[part 1 of 2: package /EcuExtract]
AUTOSAR XML (schema 4-2-1)
package /EcuExtract
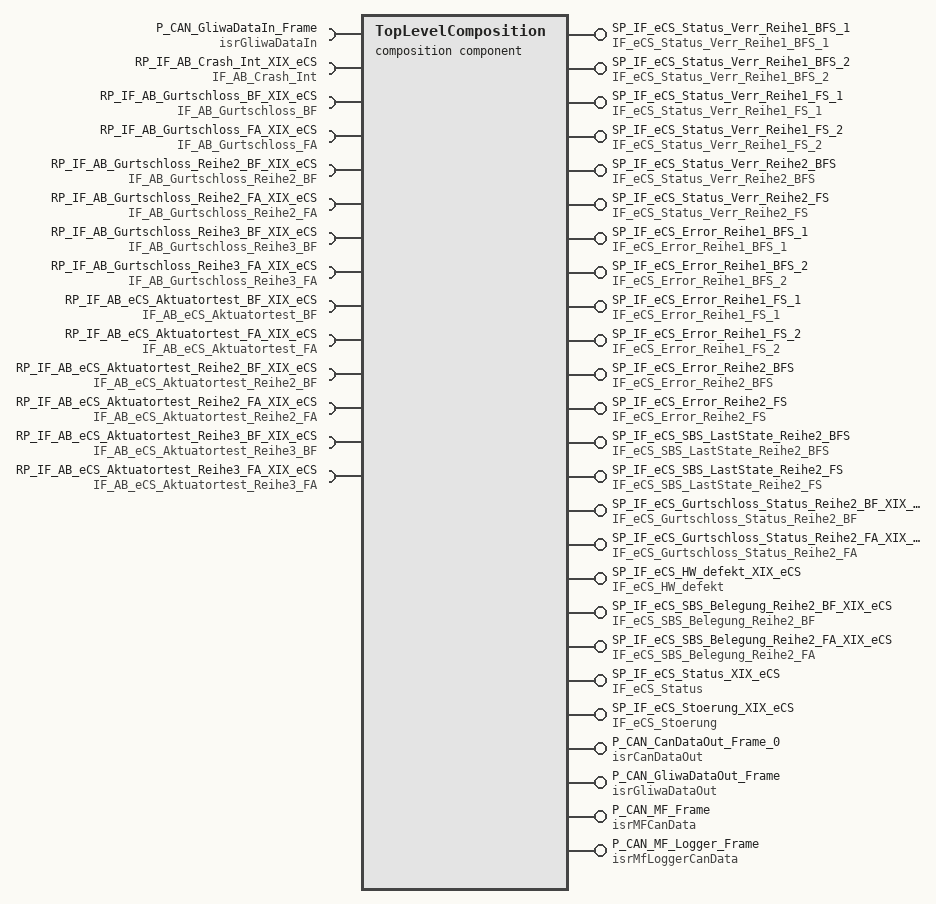
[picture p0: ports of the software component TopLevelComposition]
  composition sw component type TopLevelComposition
    require port P_CAN_GliwaDataIn_Frame: required-interface=isrGliwaDataIn
    14 x provide port:
      SP_IF_eCS_Status_Verr_Reihe1_BFS_1: provided-interface=IF_eCS_Status_Verr_Reihe1_BFS_1
      SP_IF_eCS_Status_Verr_Reihe1_BFS_2: provided-interface=IF_eCS_Status_Verr_Reihe1_BFS_2
      SP_IF_eCS_Status_Verr_Reihe1_FS_1: provided-interface=IF_eCS_Status_Verr_Reihe1_FS_1
      SP_IF_eCS_Status_Verr_Reihe1_FS_2: provided-interface=IF_eCS_Status_Verr_Reihe1_FS_2
      SP_IF_eCS_Status_Verr_Reihe2_BFS: provided-interface=IF_eCS_Status_Verr_Reihe2_BFS
      SP_IF_eCS_Status_Verr_Reihe2_FS: provided-interface=IF_eCS_Status_Verr_Reihe2_FS
      SP_IF_eCS_Error_Reihe1_BFS_1: provided-interface=IF_eCS_Error_Reihe1_BFS_1
      SP_IF_eCS_Error_Reihe1_BFS_2: provided-interface=IF_eCS_Error_Reihe1_BFS_2
      SP_IF_eCS_Error_Reihe1_FS_1: provided-interface=IF_eCS_Error_Reihe1_FS_1
      SP_IF_eCS_Error_Reihe1_FS_2: provided-interface=IF_eCS_Error_Reihe1_FS_2
      SP_IF_eCS_Error_Reihe2_BFS: provided-interface=IF_eCS_Error_Reihe2_BFS
      SP_IF_eCS_Error_Reihe2_FS: provided-interface=IF_eCS_Error_Reihe2_FS
      SP_IF_eCS_SBS_LastState_Reihe2_BFS: provided-interface=IF_eCS_SBS_LastState_Reihe2_BFS
      SP_IF_eCS_SBS_LastState_Reihe2_FS: provided-interface=IF_eCS_SBS_LastState_Reihe2_FS
    13 x require port:
      RP_IF_AB_Crash_Int_XIX_eCS: required-interface=IF_AB_Crash_Int
      RP_IF_AB_Gurtschloss_BF_XIX_eCS: required-interface=IF_AB_Gurtschloss_BF
      RP_IF_AB_Gurtschloss_FA_XIX_eCS: required-interface=IF_AB_Gurtschloss_FA
      RP_IF_AB_Gurtschloss_Reihe2_BF_XIX_eCS: required-interface=IF_AB_Gurtschloss_Reihe2_BF
      RP_IF_AB_Gurtschloss_Reihe2_FA_XIX_eCS: required-interface=IF_AB_Gurtschloss_Reihe2_FA
      RP_IF_AB_Gurtschloss_Reihe3_BF_XIX_eCS: required-interface=IF_AB_Gurtschloss_Reihe3_BF
      RP_IF_AB_Gurtschloss_Reihe3_FA_XIX_eCS: required-interface=IF_AB_Gurtschloss_Reihe3_FA
      RP_IF_AB_eCS_Aktuatortest_BF_XIX_eCS: required-interface=IF_AB_eCS_Aktuatortest_BF
      RP_IF_AB_eCS_Aktuatortest_FA_XIX_eCS: required-interface=IF_AB_eCS_Aktuatortest_FA
      RP_IF_AB_eCS_Aktuatortest_Reihe2_BF_XIX_eCS: required-interface=IF_AB_eCS_Aktuatortest_Reihe2_BF
      RP_IF_AB_eCS_Aktuatortest_Reihe2_FA_XIX_eCS: required-interface=IF_AB_eCS_Aktuatortest_Reihe2_FA
      RP_IF_AB_eCS_Aktuatortest_Reihe3_BF_XIX_eCS: required-interface=IF_AB_eCS_Aktuatortest_Reihe3_BF
      RP_IF_AB_eCS_Aktuatortest_Reihe3_FA_XIX_eCS: required-interface=IF_AB_eCS_Aktuatortest_Reihe3_FA
    11 x provide port:
      SP_IF_eCS_Gurtschloss_Status_Reihe2_BF_XIX_eCS: provided-interface=IF_eCS_Gurtschloss_Status_Reihe2_BF
      SP_IF_eCS_Gurtschloss_Status_Reihe2_FA_XIX_eCS: provided-interface=IF_eCS_Gurtschloss_Status_Reihe2_FA
      SP_IF_eCS_HW_defekt_XIX_eCS: provided-interface=IF_eCS_HW_defekt
      SP_IF_eCS_SBS_Belegung_Reihe2_BF_XIX_eCS: provided-interface=IF_eCS_SBS_Belegung_Reihe2_BF
      SP_IF_eCS_SBS_Belegung_Reihe2_FA_XIX_eCS: provided-interface=IF_eCS_SBS_Belegung_Reihe2_FA
      SP_IF_eCS_Status_XIX_eCS: provided-interface=IF_eCS_Status
      SP_IF_eCS_Stoerung_XIX_eCS: provided-interface=IF_eCS_Stoerung
      P_CAN_CanDataOut_Frame_0: provided-interface=isrCanDataOut
      P_CAN_GliwaDataOut_Frame: provided-interface=isrGliwaDataOut
      P_CAN_MF_Frame: provided-interface=isrMFCanData
      P_CAN_MF_Logger_Frame: provided-interface=isrMfLoggerCanData
    32 x component:
      ACC: type=ACC
      ATM: type=ATM
      AdcIf: type=AdcIf
      BswMIf: type=BswMIf
      CIL: type=CIL
      DIA: type=DIA
      DcmIf: type=DcmIf
      DemIf: type=DemIf
      DioIf: type=DioIf
      EFX: type=EFX
      EIM: type=EIM
      EcuMIf: type=EcuMIf
      FSM: type=FSM
      IoHwAb: type=IoHwAb
      LPM: type=LPM
      MIC: type=MIC
      McuIf: type=McuIf
      NVP: type=NVP
      NmIf: type=NmIf
      NvmIf: type=NvmIf
      OsIf: type=OsIf
      PwmIf: type=PwmIf
      RCM: type=RCM
      SAD: type=SAD
      SBC: type=SBC
      STM: type=STM
      SpiIf: type=SpiIf
      T1: type=T1
      eCS: type=eCS
      Dcm: type=Dcm
      Dem: type=Dem
      NvM: type=NvM
    connect ACC.pseAccRestartInit -> LPM.pclAccRestartInit
    connect ACC.pseCheckAccAlarmbPin -> ATM.pclCheckAccAlarmbPin
    connect ACC.psr3DAcceleration -> CIL.prr3DAcceleration
    connect ACC.psr3DAcceleration -> DIA.prr3DAcceleration
    connect ACC.psrACCServices -> FSM.prrACCServices
    connect ACC.psrAccStatusFailiureSource -> CIL.prrAccStatusFailiureSource
    connect ACC.psrAccelMtrPerSecSqd -> CIL.prrAccelMtrPerSecSqd
    connect ACC.psrAccelMtrPerSecSqd -> eCS.prrAccelMtrPerSecSqd
    connect ACC.pseAccTemperatureSpiData -> IoHwAb.pclAccSpiData
    connect DioIf.psrDioIfServices -> ACC.pclDioIfServices
    connect FSM.psrSolenoidProfile -> ACC.prrSolenoidProfile
    connect SpiIf.ptrpSpiIfServicesACC -> ACC.ptrrSpiIfServices
    connect ATM.pseAutotestServices -> FSM.pclAutotestServices
    connect ATM.pseAutotestServices -> IoHwAb.pclAutotestServices
    connect ATM.pseAutotestServices -> SAD.pclAutotestServices
    connect ATM.ptrpAtmServicesBswMIf -> BswMIf.ptrrAtmServicesBswMIf
    connect AdcIf.pseCheckAdcCalib -> ATM.pclCheckAdcCalib
    connect AdcIf.pseCheckAdc -> ATM.pclCheckAdc
    connect MIC.pseRunEepromMemoryCorruption -> ATM.pclRunEepromMemoryCorruption
    connect NvmIf.pseRunEepromMemoryNotProgrammed -> ATM.pclRunEepromMemoryNotProgrammed
    connect MIC.pseRunPFlashMemoryCorruption -> ATM.pclRunPFlashMemoryCorruption
    connect MIC.pseRunRamMemoryCorruption -> ATM.pclRunRamMemoryCorruption
    connect RCM.pseRunResetCause -> ATM.pclRunResetCause
    connect EIM.pseInjectError -> ATM.pclInjectError
    connect FSM.pseModeManagement -> ATM.pclModeManagement
    connect IoHwAb.pseCheckPowerSupplyOV -> ATM.pclCheckPowerSupplyOV
    connect IoHwAb.pseCheckPowerSupplyUV -> ATM.pclCheckPowerSupplyUV
    connect IoHwAb.pseEcuOverTemperature -> ATM.pclEcuOverTemperature
    connect McuIf.pseCheckCrcOnMcuRegisters -> ATM.pclCheckCrcOnMcuRegisters
    connect McuIf.pseCheckMcuSelfTest -> ATM.pclCheckMcuSelfTest
    connect SAD.pseCheckActuatorState -> ATM.pclCheckActuatorState
    connect SAD.pseCheckPowerStage -> ATM.pclCheckPowerStage
    connect SAD.pseCheckSolenoidOpenCircuit -> ATM.pclCheckOpenCircuit
    connect SAD.pseCheckSolenoidOvervoltage -> ATM.pclCheckSolenoidOvervoltage
    connect SAD.pseCheckSolenoidShortToGND -> ATM.pclCheckShortToGND
    connect SAD.pseCheckSolenoidShortToVBAT -> ATM.pclCheckShortToVBAT
    connect SBC.pseCheckSbcStatusInfo -> ATM.pclCheckSbcStatusInfo
    connect SBC.pseSbcWdgAutotest -> ATM.pclRunExtWDTest
    connect Dem.ASR42_Event_EVENT_ACC_STATUS_FAILURE -> ATM.pclEvtAccStatusFailure
    connect Dem.ASR42_Event_EVENT_ACTUATOR_OPEN_CIRCUIT -> ATM.pclEvtActuatorOpenCircuit
    connect Dem.ASR42_Event_EVENT_ACTUATOR_SHORT_TO_GND -> ATM.pclEvtActuatorShortToGND
    connect Dem.ASR42_Event_EVENT_ACTUATOR_SHORT_TO_VBAT -> ATM.pclEvtActuatorShortToVBAT
    connect Dem.ASR42_Event_EVENT_ACTUATOR_STATUS -> ATM.pclEvtActuatorState
    connect Dem.ASR42_Event_EVENT_ADC_CALIB -> ATM.pclEvtAdcCalibration
    connect Dem.ASR42_Event_EVENT_ADC_OUT_OF_ORDER -> ATM.pclEvtAdcOutOfOrder
    connect Dem.ASR42_Event_EVENT_DFLASH_MEM_CORRUPT -> ATM.pclEvtNvmEcc
    connect Dem.ASR42_Event_EVENT_ECU_OVER_TEMPERATURE -> ATM.pclEvtEcuoverTemperature
    connect Dem.ASR42_Event_EVENT_EXT_WDG_OUT_OF_ORDER -> ATM.pclEvtExtWdgOutOfOrder
    connect Dem.ASR42_Event_EVENT_MCU_CRC_REGISTERS -> ATM.pclEvtMcuCrcRegisters
    connect Dem.ASR42_Event_EVENT_MCU_SELFTEST -> ATM.pclEvtMcuSelftest
    connect Dem.ASR42_Event_EVENT_NVM_NOT_PRG -> ATM.pclEvtNvmNotPrg
    connect Dem.ASR42_Event_EVENT_PFLASH_MEM_CORRUPT -> ATM.pclEvtFlsEcc
    connect Dem.ASR42_Event_EVENT_POWER_STAGE_FAILIURE -> ATM.pclEvtPowerStageFailiure
    connect Dem.ASR42_Event_EVENT_POWER_SUPPLY_OV -> ATM.pclEvtPowerSupllyOV
    connect Dem.ASR42_Event_EVENT_POWER_SUPPLY_UV -> ATM.pclEvtPowerSupllyUV
    connect Dem.ASR42_Event_EVENT_RAM_MEM_CORRUPT -> ATM.pclEvtRamEcc
    connect Dem.ASR42_Event_EVENT_SBC_STATUS_FAILURE -> ATM.pclEvtSbcStatusFailiure
    connect Dem.ASR42_Event_EVENT_SOLENOID_OVERVOLTAGE -> ATM.pclEvtSolenoidOvervoltage
    connect Dem.ASR42_Event_EVENT_WARM_RESET -> ATM.pclEvtWarmReset
    connect AdcIf.prrAdcBufferServices -> IoHwAb.prrAdcBufferServices
    connect AdcIf.pseAdcIfServices -> LPM.pclAdcIfServices
    connect AdcIf.ptrpAdcIfServicesBswMIf -> BswMIf.ptrrAdcIfServicesBswMIf
    connect AdcIf.ptrpEcuMIfServicesAdcIf -> EcuMIf.ptrrEcuMIfServicesAdcIf
    connect AdcIf.pseRawAdcService -> IoHwAb.pclRawAdcService
    connect BswMIf.pseEcuStateTransitions -> NmIf.pclEcuStateTransitionBswMIf
    connect BswMIf.psePassengerOccupancyState -> IoHwAb.pclPassengerOccupancyState
    connect BswMIf.psrBswMIfServices -> FSM.prrBswMIfServices
    connect BswMIf.psrFsmSolenoidReqBswMIf -> FSM.prrEcsDiagRequest
    connect BswMIf.ptrpNmIfServicesBswMIf -> NmIf.ptrrNmIfServicesBswMIf
    connect CIL.pseSetEcuStateSignal -> BswMIf.pclCILGetEcuState
    connect CIL.ptrpCilServicesBswMIf -> BswMIf.ptrrCilServicesBswMIf
    connect DIA.ptrpDiaServicesBswMIf -> BswMIf.ptrrDiaServicesBswMIf
    connect FSM.ptrpFsmServicesBswMIf -> BswMIf.ptrrFsmServicesBswMIf
    connect LPM.ptrpLpmServicesBswMIf -> BswMIf.ptrrLpmServicesBswMIf
    connect MIC.p_ptrrMicServicesBswMIf -> BswMIf.ptrrMicServices
    connect McuIf.ptrpMcuIfServicesBswmIf -> BswMIf.ptrrMcuIfServicesBswMIf
    connect NvmIf.pseNvmIfServices -> BswMIf.pclNvmIfServices
    connect RCM.pseResetCauseNotification -> BswMIf.pclNotifyResetCause
    connect RCM.ptrpRcmServicesBswMIf -> BswMIf.ptrrRcmServicesBswMIf
    connect SAD.ptrpSadServicesBswMIf -> BswMIf.ptrrSadServicesBswMIf
    connect Dem.ASR42_OpCycle_DEM_OPCYC_POWER -> BswMIf.pclDemSetOpCycle
    delegate CIL.P_CAN_GliwaDataIn_Frame <-> outer port P_CAN_GliwaDataIn_Frame
    delegate CIL.SP_IF_eCS_Status_Verr_Reihe1_BFS_1 <-> outer port SP_IF_eCS_Status_Verr_Reihe1_BFS_1
    delegate CIL.SP_IF_eCS_Status_Verr_Reihe1_BFS_2 <-> outer port SP_IF_eCS_Status_Verr_Reihe1_BFS_2
    delegate CIL.SP_IF_eCS_Status_Verr_Reihe1_FS_1 <-> outer port SP_IF_eCS_Status_Verr_Reihe1_FS_1
    delegate CIL.SP_IF_eCS_Status_Verr_Reihe1_FS_2 <-> outer port SP_IF_eCS_Status_Verr_Reihe1_FS_2
    delegate CIL.SP_IF_eCS_Status_Verr_Reihe2_BFS <-> outer port SP_IF_eCS_Status_Verr_Reihe2_BFS
    delegate CIL.SP_IF_eCS_Status_Verr_Reihe2_FS <-> outer port SP_IF_eCS_Status_Verr_Reihe2_FS
    delegate CIL.SP_IF_eCS_Error_Reihe1_BFS_1 <-> outer port SP_IF_eCS_Error_Reihe1_BFS_1
    delegate CIL.SP_IF_eCS_Error_Reihe1_BFS_2 <-> outer port SP_IF_eCS_Error_Reihe1_BFS_2
    delegate CIL.SP_IF_eCS_Error_Reihe1_FS_1 <-> outer port SP_IF_eCS_Error_Reihe1_FS_1
    delegate CIL.SP_IF_eCS_Error_Reihe1_FS_2 <-> outer port SP_IF_eCS_Error_Reihe1_FS_2
    delegate CIL.SP_IF_eCS_Error_Reihe2_BFS <-> outer port SP_IF_eCS_Error_Reihe2_BFS
    delegate CIL.SP_IF_eCS_Error_Reihe2_FS <-> outer port SP_IF_eCS_Error_Reihe2_FS
    delegate CIL.SP_IF_eCS_SBS_LastState_Reihe2_BFS <-> outer port SP_IF_eCS_SBS_LastState_Reihe2_BFS
    delegate CIL.SP_IF_eCS_SBS_LastState_Reihe2_FS <-> outer port SP_IF_eCS_SBS_LastState_Reihe2_FS
    delegate CIL.RP_IF_AB_Crash_Int_XIX_Grundumfang_XIX_eCS <-> outer port RP_IF_AB_Crash_Int_XIX_eCS
    delegate CIL.RP_IF_AB_Gurtschloss_BF_XIX_Grundumfang_XIX_eCS <-> outer port RP_IF_AB_Gurtschloss_BF_XIX_eCS
    delegate CIL.RP_IF_AB_Gurtschloss_FA_XIX_Grundumfang_XIX_eCS <-> outer port RP_IF_AB_Gurtschloss_FA_XIX_eCS
    delegate CIL.RP_IF_AB_Gurtschloss_Reihe2_BF_XIX_Grundumfang_XIX_eCS <-> outer port RP_IF_AB_Gurtschloss_Reihe2_BF_XIX_eCS
    delegate CIL.RP_IF_AB_Gurtschloss_Reihe2_FA_XIX_Grundumfang_XIX_eCS <-> outer port RP_IF_AB_Gurtschloss_Reihe2_FA_XIX_eCS
    delegate CIL.RP_IF_AB_Gurtschloss_Reihe3_BF_XIX_Grundumfang_XIX_eCS <-> outer port RP_IF_AB_Gurtschloss_Reihe3_BF_XIX_eCS
    delegate CIL.RP_IF_AB_Gurtschloss_Reihe3_FA_XIX_Grundumfang_XIX_eCS <-> outer port RP_IF_AB_Gurtschloss_Reihe3_FA_XIX_eCS
    delegate CIL.RP_IF_AB_eCS_Aktuatortest_BF_XIX_Grundumfang_XIX_eCS <-> outer port RP_IF_AB_eCS_Aktuatortest_BF_XIX_eCS
    delegate CIL.RP_IF_AB_eCS_Aktuatortest_FA_XIX_Grundumfang_XIX_eCS <-> outer port RP_IF_AB_eCS_Aktuatortest_FA_XIX_eCS
    delegate CIL.RP_IF_AB_eCS_Aktuatortest_Reihe2_BF_XIX_Grundumfang_XIX_eCS <-> outer port RP_IF_AB_eCS_Aktuatortest_Reihe2_BF_XIX_eCS
    delegate CIL.RP_IF_AB_eCS_Aktuatortest_Reihe2_FA_XIX_Grundumfang_XIX_eCS <-> outer port RP_IF_AB_eCS_Aktuatortest_Reihe2_FA_XIX_eCS
    delegate CIL.RP_IF_AB_eCS_Aktuatortest_Reihe3_BF_XIX_Grundumfang_XIX_eCS <-> outer port RP_IF_AB_eCS_Aktuatortest_Reihe3_BF_XIX_eCS
    delegate CIL.RP_IF_AB_eCS_Aktuatortest_Reihe3_FA_XIX_Grundumfang_XIX_eCS <-> outer port RP_IF_AB_eCS_Aktuatortest_Reihe3_FA_XIX_eCS
    delegate CIL.SP_IF_eCS_Gurtschloss_Status_Reihe2_BF_XIX_Grundumfang_XIX_eCS <-> outer port SP_IF_eCS_Gurtschloss_Status_Reihe2_BF_XIX_eCS
    delegate CIL.SP_IF_eCS_Gurtschloss_Status_Reihe2_FA_XIX_Grundumfang_XIX_eCS <-> outer port SP_IF_eCS_Gurtschloss_Status_Reihe2_FA_XIX_eCS
    delegate CIL.SP_IF_eCS_HW_defekt_XIX_Grundumfang_XIX_eCS <-> outer port SP_IF_eCS_HW_defekt_XIX_eCS
    delegate CIL.SP_IF_eCS_SBS_Belegung_Reihe2_BF_XIX_Grundumfang_XIX_eCS <-> outer port SP_IF_eCS_SBS_Belegung_Reihe2_BF_XIX_eCS
    delegate CIL.SP_IF_eCS_SBS_Belegung_Reihe2_FA_XIX_Grundumfang_XIX_eCS <-> outer port SP_IF_eCS_SBS_Belegung_Reihe2_FA_XIX_eCS
    delegate CIL.SP_IF_eCS_Status_XIX_Grundumfang_XIX_eCS <-> outer port SP_IF_eCS_Status_XIX_eCS
    delegate CIL.SP_IF_eCS_Stoerung_XIX_Grundumfang_XIX_eCS <-> outer port SP_IF_eCS_Stoerung_XIX_eCS
    connect CIL.psrCILData -> FSM.prrCILData
    connect CIL.psrCrashStatus -> FSM.prrCrashStatus
    connect CIL.psrEcsDiagRequest -> FSM.prrEcsDiagRequest
    connect FSM.pseModeManagement -> CIL.pclModeManagement
    connect FSM.psrSolenoidStuckStatus -> CIL.prrSolenoidStuckStatus
    connect FSM.psrSolenoidProfile -> CIL.pclSolenoidProfile
    connect FSM.psrSolenoidState -> CIL.prrSolenoidState
    connect IoHwAb.pseAccSensor -> CIL.pclAccSensor
    connect IoHwAb.pseEcuCharacteristics -> CIL.pclEcuCharacterstics
    connect IoHwAb.pseConvAdcService -> CIL.pclConvAdcService
    connect IoHwAb.pseMcuCharacteristics -> CIL.pclMcuCharacteristics
    connect IoHwAb.psePtcSensor -> CIL.pclPtcSensor
    connect IoHwAb.pseSolenoidCharacterstics -> CIL.pclSolenoidCharacteristics
    connect IoHwAb.psrBuckleStatus -> CIL.prrBuckleStatus
    connect IoHwAb.psrSeatOccupancySensorStatus -> CIL.prrSeatOccupancySensorStatus
    connect SAD.pseSolenoidPWM -> CIL.prrSolenoidPWM
    connect SAD.pseSolenoidStep -> CIL.pclSolenoidStep
    connect SAD.psrSolenoidOpenCircutStatus -> CIL.prrSolenoidOCStatus
    connect SAD.psrSolenoidOvervoltageStatus -> CIL.prrSolenoidOvervoltageStatus
    connect SAD.psrSolenoidShortToGndStatus -> CIL.prrSolenoidShortToGndStatus
    connect SAD.psrSolenoidShortToVccStatus -> CIL.prrSolenoidShortToVccStatus
    connect SBC.psrSbcStatusFailiureSource -> CIL.prrSbcStatusFailiureSource
    connect eCS.psrEcsAlgoData -> CIL.prrEcsAlgoData
    delegate CIL.P_CAN_CanDataOut_Frame_0 <-> outer port P_CAN_CanDataOut_Frame_0
    delegate CIL.P_CAN_GliwaDataOut_Frame <-> outer port P_CAN_GliwaDataOut_Frame
    delegate CIL.P_CAN_MF_Frame <-> outer port P_CAN_MF_Frame
    delegate CIL.P_CAN_MF_Logger_Frame <-> outer port P_CAN_MF_Logger_Frame
    connect DIA.pseEcsDiagRequest -> FSM.prrEcsDiagRequest
    connect NvmIf.pseNvmIfServices -> DIA.pclNvmIfServices
    connect RCM.pseResetCause -> DIA.pclResetCause
    connect FSM.pseFsmServices -> DIA.pclFsmServices
    connect IoHwAb.pseAccSensor -> DIA.pclAccSensor
    connect IoHwAb.pseConvAdcService -> DIA.pclConvAdcService
    connect IoHwAb.pseMcuCharacteristics -> DIA.pclMcuCharacteristics
    connect IoHwAb.pseEcuCharacteristics -> DIA.pclEcuCharacterstics
    connect IoHwAb.psePtcSensor -> DIA.pclPtcSensor
    connect NVP.pseNvpBlockDataDia -> DIA.pseNvpBlockData
    connect RCM.pseResetCauseNotification -> DIA.pclResetCauseNotification
    connect STM.pseSystemTime -> DIA.pclSystemTime
    connect DIA.pseCallBackDCMRequestServices_CBReqServInd_1 -> Dcm.CallBackDCMRequestServices_CBReqServInd_1
    connect DIA.pseDID_0236_ProgrammingDataElockEcu -> Dcm.DataServices_DID_0236_ProgrammingDataElockEcuData
    connect DIA.pseDID_023E_WSCForProgrammingElockEcu -> Dcm.DataServices_DID_023E_WSCForProgrammingElockEcuData
    connect DIA.pseDID_0407_VWLogicalSoftwareBlockCounterOfProgrammingAttempts -> Dcm.DataServices_DID_0407_VWLogicalSoftwareBlockCounterOfProgrammingAttemptsData
    connect DIA.pseDID_040F_VWLogicalSoftwareBlockLockValue -> Dcm.DataServices_DID_040F_VWLogicalSoftwareBlockLockValueData
    connect DIA.pseDID_0410_BootloaderTPBlocksize -> Dcm.DataServices_DID_0410_BootloaderTPBlocksizeData
    connect DIA.pseDID_0448_ProgrammingPreconditions -> Dcm.DataServices_DID_0448_ProgrammingPreconditionsData
    connect DIA.pseDID_4024_SWSystemTime -> Dcm.DataServices_DID_4024_SWSystemTimeData
    connect DIA.pseDID_F15B_FingerprintAndProgrammingDateOfLogicalSoftwareBlocks -> Dcm.DataServices_DID_F15B_FingerprintAndProgrammingDateOfLogicalSoftwareBlocksData
    connect DIA.pseDID_F187_VWSparePartNumber -> Dcm.DataServices_DID_F187_VWSparePartNumberData
    connect DIA.pseDID_F18C_ECUSerialNumberData -> Dcm.DataServices_DID_F18C_ECUSerialNumberData
    connect DIA.pseDID_F191_VWECUHardwareNumber -> Dcm.DataServices_DID_F191_VWECUHardwareNumberData
    connect DIA.pseDID_F197_VWSystemNameOrEngineType -> Dcm.DataServices_DID_F197_VWSystemNameOrEngineTypeData
    connect DIA.pseDID_F19E_ASAMODXFileIdentifier -> Dcm.DataServices_DID_F19E_ASAMODXFileIdentifierData
    connect DIA.pseDID_F1A2_ASAMODXFileVersion -> Dcm.DataServices_DID_F1A2_ASAMODXFileVersionData
    connect DIA.pseDID_F1A3_VWECUHardwareVersionNumber -> Dcm.DataServices_DID_F1A3_VWECUHardwareVersionNumberData
    connect DIA.pseDID_F1AB_VWLogicalSoftwareBlockVersion -> Dcm.DataServices_DID_F1AB_VWLogicalSoftwareBlockVersionData
    connect DIA.pseDID_F1B4_TechnicalSpecificationsVersion -> Dcm.DataServices_DID_F1B4_TechnicalSpecificationsVersionData
    connect DIA.pseDID_F1D5_FDSProject -> Dcm.DataServices_DID_F1D5_FDSProjectData
    connect DIA.pseDID_F1DF_ECUProgrammingInformation -> Dcm.DataServices_DID_F1DF_ECUProgrammingInformationData
    connect DIA.pseDID_FD00_HWVersion -> Dcm.DataServices_DID_FD00_HWVersionData
    connect DIA.pseDID_FD01_SWVersion -> Dcm.DataServices_DID_FD01_SWVersionData
    connect DIA.pseDID_FD03_AEETraceabilityNumber -> Dcm.DataServices_DID_FD03_AEETraceabilityNumberData
    connect DIA.pseDID_FD08_ResetCause -> Dcm.DataServices_DID_FD08_ResetCauseData
    connect DIA.pseDID_FD09_LastWarmResetParam -> Dcm.DataServices_DID_FD09_LastWarmResetParamData
    connect DIA.pseDID_FD0F_BatteryMeasure -> Dcm.DataServices_DID_FD0F_BatteryMeasureData
    connect DIA.pseDID_FD10_ECUTemperature -> Dcm.DataServices_DID_FD10_ECUTemperatureData
    connect DIA.pseDID_FD62_EccOccurenceNb -> Dcm.DataServices_DID_FD62_EccOccurenceNbData
    connect DIA.pseDID_FD8B_ECUManufacturingDate -> Dcm.DataServices_DID_FD8B_ECUManufacturingDateData
    connect DIA.pseDID_FD8C_AssemblySerialNumber -> Dcm.DataServices_DID_FD8C_AssemblySerialNumber
    connect DIA.pseDID_FDE0_EcsVariant -> Dcm.DataServices_DID_FDE0_EcsVariantData
    connect DIA.pseDID_FDE1_EcsParameters -> Dcm.DataServices_DID_FDE1_EcsParametersData
    connect DIA.pseDID_FDE2_EcsAccOffsets -> Dcm.DataServices_DID_FDE2_AccOffsetData
    connect DIA.pseDID_FDE3_EcsProfiles -> Dcm.DataServices_DID_FDE3_EcsProfilesData
    connect DIA.pseDID_FDE4_EcsSteps -> Dcm.DataServices_DID_FDE4_EcsStepsData
    connect DIA.pseDID_FDE5_EcsAccLowPass -> Dcm.DataServices_DID_FDE5_EcsAccLowPassData
    connect DIA.pseDID_FDE7_EcsAlgoOutputDelay -> Dcm.DataServices_DID_FDE7_AlgoOutputDelayData
    connect DIA.pseDID_FDE9_SensitivityLutData -> Dcm.DataServices_DID_FDE9_SensitivityLutData
    connect DIA.pseDID_FDEA_SensitivityOptData -> Dcm.DataServices_DID_FDEA_SensitivityOptData
    connect DIA.pseDID_FDFF_MeasurementFrameRamConf -> Dcm.DataServices_DID_FDFF_MeasurementFrameConfDataRam
    connect DIA.pseDID_FE00_AllEventStatusesRead -> Dcm.DataServices_DID_FE00_AllEventStatusesRead
    connect DIA.pseDID_FEFF_MeasurementFramesConf -> Dcm.DataServices_DID_FEFF_MeasurementFramesConfData
    connect DIA.pseDID_F189_VWApplicationSoftwareVersionNumber -> Dcm.DataServices_DID_F189_VWApplicationSoftwareVersionNumberData
    connect DIA.pseRoutineControl_AccAngleOffsetCalibration -> Dcm.RoutineServices_DcmDspRoutineAccAngleOffsetCalibration
    connect DIA.pseRoutineControl_AccCalib -> Dcm.RoutineServices_DcmDspRoutineAccCalib
    connect DIA.pseRoutineControl_CheckProgrammingPreconditions -> Dcm.RoutineServices_DcmDspRoutineRoutineCheckProgrammingPreconditions
    connect DIA.pseRoutineControl_EcuTempCalibration -> Dcm.RoutineServices_DcmDspRoutineEcuTempCalibration
    connect DIA.pseRoutineControl_LockSolenoid -> Dcm.RoutineServices_DcmDspRoutineLockSolenoid
    connect DIA.pseRoutineControl_LockUnlockECU -> Dcm.RoutineServices_DcmDspRoutineCtrl_Lock_UnlockECU
    connect DIA.pseRoutineControl_ProcessModeRoutine -> Dcm.RoutineServices_DcmDspRoutineProcessMode
    connect DIA.pseSecurityAccess -> Dcm.SecurityAccess_DcmDspSecurityAlv
    connect DIA.pseServiceRequestSupplierNotification -> Dcm.ServiceRequestSupplierNotification_DcmDslServiceRequestSupplierNotification
    connect Dem.GeneralEvtInfo -> DIA.pclDemServices
    connect NVP.pseNvpBlockDataDcmIf -> DcmIf.pseNvpBlockData
    connect NvmIf.pseNvmIfServices -> DcmIf.pclNvmIfServices
    connect DemIf.pseDemIfEventServices -> FSM.pclDemIfEventSerices
    connect DioIf.psrDioIfServices -> IoHwAb.pclDioIfServices
    connect DioIf.ptrpEcuMIfServicesDioIf -> EcuMIf.ptrrEcuMIfServicesDioIf
    connect DioIf.psrDioIfServices -> SAD.pclDioIfServices
    connect EFX.pseEfxServices -> IoHwAb.pclEfxServices
    connect FSM.psrSolenoidProfile -> EIM.prrFSMSolenoidProfile
    connect Dem.ASR42_Event_EVENT_ADC_OUT_OF_ORDER -> EIM.pclDemDiagMonitor
    connect RCM.pseResetCauseNotification -> EcuMIf.pclNotifyResetCause
    connect SBC.pseSbcStatus -> EcuMIf.pclSbcServices
    connect FSM.pseModeManagement -> IoHwAb.pclModeManagement
    connect FSM.pseModeManagement -> SAD.pclModeManagement
    connect FSM.pseModeManagement -> eCS.pclModeManagement
    connect FSM.pseFsmServices -> IoHwAb.pclUnlockTimeout
    connect FSM.psrSolenoidProfile -> SAD.prrSolenoidProfile
    connect FSM.psrSolenoidStuckStatus -> SAD.prrSolenoidStuckStatus
    connect FSM.psrSolenoidProfile -> IoHwAb.pclSolenoidProfile
    connect FSM.psrSolenoidState -> SAD.prrSolenoidState
    connect IoHwAb.pseConvAdcService -> FSM.pclConvAdcService
    connect IoHwAb.psrSolenoidConfirmation -> FSM.prrSolenoidConfirmation
    connect NvmIf.pseNvmIfServices -> FSM.pclNvmIfServices
    connect SAD.pseDiagRequestServices -> FSM.prrEcsDiagRequest
    connect SAD.psrSolenoidOpenCircutStatus -> FSM.prrSolenoidOpenCircuitStatus
    connect SAD.psrSolenoidOvervoltageStatus -> FSM.prrSolenoidOverVoltageStatus
    connect SAD.psrSolenoidShortToGndStatus -> FSM.prrSolenoidShortToGndStatus
    connect eCS.psrEcsAlgoData -> FSM.prrEcsAlgoFlag
    connect Dem.GeneralEvtInfo -> FSM.pclDemServices
    connect IoHwAb.pseConvAdcService -> SAD.pclConvAdcService
    connect IoHwAb.pseHandleSeatCurrentCircuit -> LPM.pclHandleSeatCurrentCircuit
    connect IoHwAb.pseLowPowerWakeUp -> LPM.pclLowPowerWakeUp
    connect NvmIf.pseNvmIfServices -> IoHwAb.pclNvmIfServices
    connect SAD.pseSolenoidPWM -> IoHwAb.prrSolenoidPwm
    connect SAD.pseSolenoidStep -> IoHwAb.pclSolenoidStep
    connect SAD.psrSolenoidElectricalCharacteristics -> IoHwAb.prrSolenoidElectricalCharacteristics
    connect SBC.pseSbcServices -> LPM.pclSbcServices
    connect MIC.p_ptrrMicServicesOsIf -> OsIf.ptrrMicServices
    connect NvmIf.pseNvmIfServices -> MIC.pclNvmIfServices
    connect RCM.pseResetCauseNotification -> MIC.pclResetCauseNotification
    connect RCM.pseResetCause -> MIC.pclResetCause
    connect SBC.pseSbcStatus -> MIC.pclSbcServices
    connect NvmIf.pseNvmIfServices -> RCM.pclNvmIfServices
    connect NvM.PS_ASR42_ACC_AXIS_ANGLE_CALIBRATION -> NvmIf.pclNvmService_AccAngleCalibration
    connect NvM.PS_ASR42_AEE_TRACEABILITY_NUMBER -> NvmIf.pclNvmService_AeeTraceabilityNumber
    connect NvM.PS_ASR42_ALV_NVM_VERSION -> NvmIf.pclNvmService_AlvNvmVersion
    connect NvM.PS_ASR42_APP_SOFTWARE_VERSION_NUMBER -> NvmIf.pclNvmService_OemAppSwVersionNumber
    connect NvM.PS_ASR42_AUTOTEST_ENABLE_PARAM -> NvmIf.pclNvmServices_AutotestEnableParam
    connect NvM.PS_ASR42_AUTOTEST_PARAM -> NvmIf.pclNvmServices_AutotestParam
    connect NvM.PS_ASR42_BLOCK_FBL -> NvmIf.pclNvmService_OemFlashBootloader
    connect NvM.PS_ASR42_ECC_COUNTERS -> NvmIf.pclNvmServices_EccCounters
    connect NvM.PS_ASR42_ECS_ACC_LOWPASS -> NvmIf.pclNvmService_EcsAccLowPass
    connect NvM.PS_ASR42_ECS_ACC_OFFSETS -> NvmIf.pclNvmService_EcsAccOffsets
    connect NvM.PS_ASR42_ECS_ALGO_OUTPUT_DELAY -> NvmIf.pclNvmService_EcsAlgoOutputDelay
    connect NvM.PS_ASR42_ECS_PARAMETERS -> NvmIf.pclNvmService_EcsParameters
    connect NvM.PS_ASR42_ECS_PROFILES -> NvmIf.pclNvmService_EcsProfiles
    connect NvM.PS_ASR42_ECS_SENSITIVITY_LUT -> NvmIf.pclNvmService_EcsSensitivityLUT
    connect NvM.PS_ASR42_ECS_SENSITIVITY_OPT -> NvmIf.pclNvmService_EcsSensitivityOPT
    connect NvM.PS_ASR42_ECS_STEPS -> NvmIf.pclNvmService_EcsSteps
    connect NvM.PS_ASR42_ECS_VARIANT -> NvmIf.pclNvmService_EcsVariant
    connect NvM.PS_ASR42_ECU_ASSEMBLY_SERIAL_NUMBER -> NvmIf.pclNvmService_AssemblySerialNumber
    connect NvM.PS_ASR42_ECU_SERIAL_NUMBER -> NvmIf.pclNvmService_OemEcuSerialNumber
    connect NvM.PS_ASR42_ECU_STATE_TIMING_PARAMETERS -> NvmIf.pclNvmService_EcuStateTimingParam
    connect NvM.PS_ASR42_ECU_TEMP_CALIBRATION -> NvmIf.pclNvmServices_EcuTempCalibration
    connect NvM.PS_ASR42_EOL_COUNTERS -> NvmIf.pclNvmService_EolCounters
    connect NvM.PS_ASR42_HARDWARE_NUMBER -> NvmIf.pclNvmService_OemHardwareNumber
    connect NvM.PS_ASR42_HARDWARE_VERSION_NUMBER -> NvmIf.pclNvmService_OemHardwareVersionNumber
    connect NvM.PS_ASR42_HW_PART_NUMBER -> NvmIf.pclNvmService_HwPartNumber
    connect NvM.PS_ASR42_LOCK_UNLOCK_ECU -> NvmIf.pclNvmService_LockUnlockECU
    connect NvM.PS_ASR42_LOGICAL_SW_BLOCK_VERSION -> NvmIf.pclNvmService_OemLogicalBlockVersion
    connect NvM.PS_ASR42_MEASUREMENT_FRAME_CONFIG -> NvmIf.pclNvmServices_MeasFrameCfg
    connect NvM.PS_ASR42_MEAS_FRAME_RAM_ADDR_CFG -> NvmIf.pclNvmServices_MeasFrameRamCfg
    connect NvM.PS_ASR42_NVM_BLOCK_DEM_DEFAULT -> NvmIf.pclNvmServices_DemDefault
    connect NvM.PS_ASR42_ODX_FILE_IDENTIFIER -> NvmIf.pclNvmService_OemOdxIdentifier
    connect NvM.PS_ASR42_ODX_FILE_VERSION -> NvmIf.pclNvmService_OemOdxVersion
    connect NvM.PS_ASR42_PHYS_MEASUREMENTS -> NvmIf.pclNvmService_PhysicalMeasurements
    connect NvM.PS_ASR42_PROCESS_MODE -> NvmIf.pclNvmServices_ProcessMode
    connect NvM.PS_ASR42_SBS_LAST_STATE -> NvmIf.pclNvmService_SBSLastState
    connect NvM.PS_ASR42_SOLENOID_PARAM -> NvmIf.pclNvmService_SolenoidParam
    connect NvM.PS_ASR42_SPARE_PART_NUMBER -> NvmIf.pclNvmService_OemSparePartNumber
    connect NvM.PS_ASR42_SYSTEM_NAME_OR_ENGINE_TYPE -> NvmIf.pclNvmService_OemSystemName
    connect NvM.PS_ASR42_WARM_RESET_COUNTERS -> NvmIf.pclNvmServices_WarmResetCounters
    connect RCM.pseOSErrorReport -> OsIf.pclRcmServices
    connect RCM.pseResetCauseNotification -> OsIf.pclResetCauseNotification
    connect PwmIf.psePwmServices -> SAD.pclPwmServices
    connect RCM.pseResetCauseNotification -> SBC.pclResetCauseNotification
    connect RCM.pseResetCause -> SBC.pclResetCause
    connect SBC.pseSbcStatus -> RCM.pclSbcWdgServices
    connect Dem.ASR42_EvtInfo_EVENT_ACTUATOR_OPEN_CIRCUIT -> SAD.pclEvtActuatorOpenCircuit
    connect Dem.ASR42_EvtInfo_EVENT_ACTUATOR_SHORT_TO_GND -> SAD.pclEvtActuatorShortToGround
    connect Dem.ASR42_EvtInfo_EVENT_ACTUATOR_SHORT_TO_VBAT -> SAD.pclEvtActuatorShortToVbat
    connect Dem.ASR42_EvtInfo_EVENT_SOLENOID_OVERVOLTAGE -> SAD.pclEvtSolenoidOvervoltage
    connect SpiIf.ptrpSpiIfServicesSBC -> SBC.ptrrSpiIfServices
    connect Dem.Dcm -> Dcm.DcmIf
  system ECU_Application: category=ECU_EXTRACT, system-version=1.0.0
    system mapping DummyEcuExtractSysMapping
    root-software-compositions:
      root sw composition prototype TopLevelCompositionPrototype: flat-map=FlatMap, software-composition=TopLevelComposition
